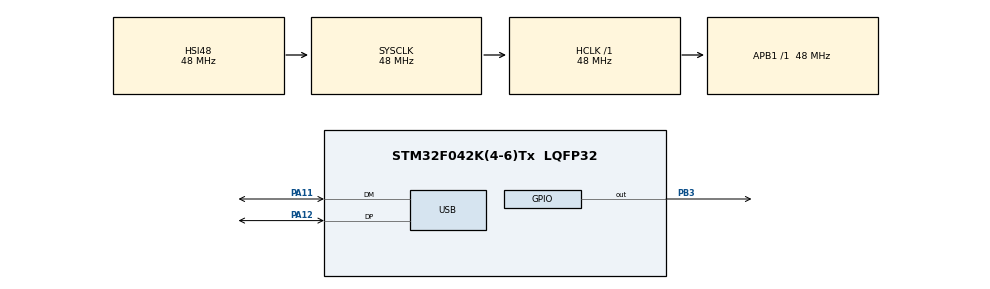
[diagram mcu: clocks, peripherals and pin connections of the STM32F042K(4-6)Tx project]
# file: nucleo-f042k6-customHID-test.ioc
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Mcu.Family=STM32F0
Mcu.Name=STM32F042K(4-6)Tx
Mcu.Package=LQFP32
NVIC.USB_IRQn=true\:0\:0\:false\:false\:true\:false\:true\:true
PA11.Mode=Device
PA11.Signal=USB_DM
PA12.Mode=Device
PA12.Signal=USB_DP
PA13.Mode=Serial_Wire
PA13.Signal=SYS_SWDIO
PA14.Mode=Serial_Wire
PA14.Signal=SYS_SWCLK
PB3.Signal=GPIO_Output
ProjectManager.HeapSize=0x200
ProjectManager.StackSize=0x400
ProjectManager.TargetToolchain=STM32CubeIDE
RCC.AHBFreq_Value=48000000
RCC.APB1Freq_Value=48000000
RCC.APB1TimFreq_Value=48000000
RCC.HCLKFreq_Value=48000000
RCC.SYSCLKFreq_VALUE=48000000
RCC.SYSCLKSource=RCC_SYSCLKSOURCE_HSI48
USB_DEVICE.CLASS_NAME_FS=CUSTOM_HID
USB_DEVICE.USBD_CUSTOM_HID_REPORT_DESC_SIZE=33
USB_DEVICE.VirtualMode=CustomHid
USB_DEVICE.VirtualModeFS=Custom_Hid_FS
VP_USB_DEVICE_VS_USB_DEVICE_CUSTOM_HID_FS.Mode=CUSTOM_HID_FS
board=custom

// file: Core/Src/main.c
/* USER CODE BEGIN Header */
/**
  ******************************************************************************
  * @file           : main.c
  * @brief          : Main program body
  ******************************************************************************
  * @attention
  *
  * Copyright (c) 2025 STMicroelectronics.
  * All rights reserved.
  *
  * This software is licensed under terms that can be found in the LICENSE file
  * in the root directory of this software component.
  * If no LICENSE file comes with this software, it is provided AS-IS.
  *
  ******************************************************************************
  */
/* USER CODE END Header */
#include "main.h"
#include "usb_device.h"

/* USER CODE BEGIN PV */
uint8_t tx_buffer[64];		//Variable to store the output data
uint8_t report_buffer[64];		//Variable to receive the report buffer
uint8_t flag = 0;			//Variable to store the button flag
uint8_t flag_rx = 0;			//Variable to store the reception flag

//extern the USB handler
extern USBD_HandleTypeDef hUsbDeviceFS;
/* USER CODE END PV */

void SystemClock_Config(void);
static void MX_GPIO_Init(void);

int main(void)
{

  /* MCU Configuration--------------------------------------------------------*/

  /* Reset of all peripherals, Initializes the Flash interface and the Systick. */
  HAL_Init();

  /* Configure the system clock */
  SystemClock_Config();

  /* Initialize all configured peripherals */
  MX_GPIO_Init();
  MX_USB_DEVICE_Init();
  /* USER CODE BEGIN 2 */
    //To fill the buffer
    for (uint8_t i=0; i<64; i++)
    {
  tx_buffer[i] = i;
    }
  /* USER CODE END 2 */

    /* Infinite loop */
    /* USER CODE BEGIN WHILE */
    while (1)
    {
    if (flag_rx == 1)
    {
    //Check if the first byte of the report buffer equals 1
    if (report_buffer[0] == 1)
    {
  //Turn the user LED on
  //HAL_GPIO_WritePin(LED3_GPIO_Port, LED3_Pin, SET);
    }

    //Check if the first byte of the report buffer equals 2
    else if (report_buffer[0] == 2)
    {
  //Turn the user LED off
  //HAL_GPIO_WritePin(LED3_GPIO_Port, LED3_Pin, RESET);
    }

    flag_rx = 0;
    }

    //To send the output data when the button is pressed
    if (flag==1)
    {
    USBD_CUSTOM_HID_SendReport(&hUsbDeviceFS, tx_buffer, 64);

    flag = 0;
    }

  /* USER CODE END WHILE */

  }
}

void SystemClock_Config(void)
{
  RCC_OscInitTypeDef RCC_OscInitStruct = {0};
  RCC_ClkInitTypeDef RCC_ClkInitStruct = {0};
  RCC_PeriphCLKInitTypeDef PeriphClkInit = {0};

  /** Initializes the RCC Oscillators according to the specified parameters
  * in the RCC_OscInitTypeDef structure.
  */
  RCC_OscInitStruct.OscillatorType = RCC_OSCILLATORTYPE_HSI48;
  RCC_OscInitStruct.HSI48State = RCC_HSI48_ON;
  RCC_OscInitStruct.PLL.PLLState = RCC_PLL_NONE;
  if (HAL_RCC_OscConfig(&RCC_OscInitStruct) != HAL_OK)
  {
    Error_Handler();
  }

  /** Initializes the CPU, AHB and APB buses clocks
  */
  RCC_ClkInitStruct.ClockType = RCC_CLOCKTYPE_HCLK|RCC_CLOCKTYPE_SYSCLK
                              |RCC_CLOCKTYPE_PCLK1;
  RCC_ClkInitStruct.SYSCLKSource = RCC_SYSCLKSOURCE_HSI48;
  RCC_ClkInitStruct.AHBCLKDivider = RCC_SYSCLK_DIV1;
  RCC_ClkInitStruct.APB1CLKDivider = RCC_HCLK_DIV1;

  if (HAL_RCC_ClockConfig(&RCC_ClkInitStruct, FLASH_LATENCY_1) != HAL_OK)
  {
    Error_Handler();
  }
  PeriphClkInit.PeriphClockSelection = RCC_PERIPHCLK_USB;
  PeriphClkInit.UsbClockSelection = RCC_USBCLKSOURCE_HSI48;

  if (HAL_RCCEx_PeriphCLKConfig(&PeriphClkInit) != HAL_OK)
  {
    Error_Handler();
  }
}

static void MX_GPIO_Init(void)
{
  GPIO_InitTypeDef GPIO_InitStruct = {0};

  /* GPIO Ports Clock Enable */
  __HAL_RCC_GPIOA_CLK_ENABLE();
  __HAL_RCC_GPIOB_CLK_ENABLE();

  /*Configure GPIO pin Output Level */
  HAL_GPIO_WritePin(GPIOB, GPIO_PIN_3, GPIO_PIN_RESET);

  /*Configure GPIO pin : PB3 */
  GPIO_InitStruct.Pin = GPIO_PIN_3;
  GPIO_InitStruct.Mode = GPIO_MODE_OUTPUT_PP;
  GPIO_InitStruct.Pull = GPIO_NOPULL;
  GPIO_InitStruct.Speed = GPIO_SPEED_FREQ_LOW;
  HAL_GPIO_Init(GPIOB, &GPIO_InitStruct);

}

/* USER CODE BEGIN 4 */

//If the button is pressed, set button flag variable
void HAL_GPIO_EXTI_Callback(uint16_t GPIO_Pin)
{
flag = 1;
}

/* USER CODE END 4 */

void Error_Handler(void)
{
  __disable_irq();
  while (1)
  {
  }
}
